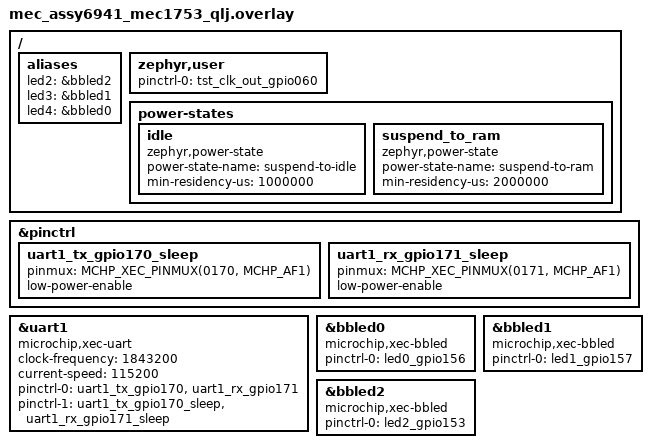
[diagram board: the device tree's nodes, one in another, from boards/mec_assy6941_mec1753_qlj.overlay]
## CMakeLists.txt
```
# Copyright (c) 2026 Microchip Technology Inc.
#
# SPDX-License-Identifier: Apache-2.0
#
cmake_minimum_required(VERSION 3.20.0)

find_package(Zephyr REQUIRED HINTS $ENV{ZEPHYR_BASE})
project(microchip_xec_pm_device)

file(GLOB app_sources src/*.c)

target_sources(app PRIVATE ${app_sources})
```

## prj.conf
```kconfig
# Enable config log
CONFIG_STDOUT_CONSOLE=y
CONFIG_LOG=y
CONFIG_LOG_BUFFER_SIZE=8096

CONFIG_LED=y

# use pseudo-random data for non-cryptographic test patterns
CONFIG_TEST_RANDOM_GENERATOR=y

# Use kernel triggered PM and driver PM_DEVICE
CONFIG_PM=y
CONFIG_PM_DEVICE=y

# make stepping code easier
#CONFIG_DEBUG=y
```

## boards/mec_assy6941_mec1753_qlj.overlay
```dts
/*
 * Copyright (c) 2026 Microchip Technology Inc.
 *
 * SPDX-License-Identifier: Apache-2.0
 */

/* mec_assy6941 EVB
 *
 * Set VTR2 to +3.3V
 * J68 2x8 1-2
 *
 */

#include <zephyr/dt-bindings/gpio/microchip-xec-gpio.h>

/* define sleep states for I2C pins */
&pinctrl {
	uart1_tx_gpio170_sleep: uart1_tx_gpio170_sleep {
		pinmux = <MCHP_XEC_PINMUX(0170, MCHP_AF1)>;
		low-power-enable;
	};

	uart1_rx_gpio171_sleep: uart1_rx_gpio171_sleep {
		pinmux = <MCHP_XEC_PINMUX(0171, MCHP_AF1)>;
		low-power-enable;
	};
};

/ {
	aliases {
		led2 = &bbled2;
		led3 = &bbled1;
		led4 = &bbled0;
	};

	/* Configure GPIO060 as test PLL clock out.
	 * We scope this pin to observe if PLL is turned off in deep sleep (suspend).
	 */
	zephyr,user {
		pinctrl-0 = <&tst_clk_out_gpio060>;
		pinctrl-names = "default";
	};

	power-states {
		idle: idle {
			compatible = "zephyr,power-state";
			power-state-name = "suspend-to-idle";
			min-residency-us = <1000000>;
		};

		suspend_to_ram: suspend_to_ram {
			compatible = "zephyr,power-state";
			power-state-name = "suspend-to-ram";
			min-residency-us = <2000000>;
		};
	};
};

&uart1 {
	compatible = "microchip,xec-uart";
	status = "okay";
	clock-frequency = <1843200>;
	current-speed = <115200>;
	pinctrl-0 = <&uart1_tx_gpio170 &uart1_rx_gpio171>;
	pinctrl-1 = <&uart1_tx_gpio170_sleep &uart1_rx_gpio171_sleep>;
	pinctrl-names = "default", "sleep";
};

&bbled0 {
	compatible = "microchip,xec-bbled";
	pinctrl-0 = <&led0_gpio156>;
	pinctrl-names = "default";
	status = "okay";
};

&bbled1 {
	compatible = "microchip,xec-bbled";
	pinctrl-0 = <&led1_gpio157>;
	pinctrl-names = "default";
	status = "okay";
};

&bbled2 {
	compatible = "microchip,xec-bbled";
	pinctrl-0 = <&led2_gpio153>;
	pinctrl-names = "default";
	status = "okay";
};
```

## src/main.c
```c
/*
 * Copyright (c) 2026 Microchip Technology Inc.
 *
 * SPDX-License-Identifier: Apache-2.0
 */

/*
 * PM device sample application
 * UART1 is used as the Zephyr console and shell
 */

#include <soc.h>
#include <string.h>
#include <zephyr/kernel.h>
#include <zephyr/device.h>
#include <zephyr/devicetree.h>
#include <zephyr/drivers/gpio.h>
#include <zephyr/drivers/led.h>
#include <zephyr/drivers/pinctrl.h>
#include <zephyr/dt-bindings/pinctrl/mchp-xec-pinctrl.h>
#include <zephyr/logging/log.h>
#include <zephyr/logging/log_ctrl.h>
#include <zephyr/pm/pm.h>
#include <zephyr/pm/device.h>
#include <zephyr/pm/policy.h>
#include <zephyr/pm/state.h>

LOG_MODULE_REGISTER(app, CONFIG_LOG_DEFAULT_LEVEL);

#define BOARD_LED2_NODE DT_ALIAS(led2)
#define BOARD_LED3_NODE DT_ALIAS(led3)
#define BOARD_LED4_NODE DT_ALIAS(led4)

#define ZEPHYR_CONSOLE_UART_NODE DT_CHOSEN(zephyr_console)

#define ZEPHYR_USER_NODE DT_PATH(zephyr_user)

/* Pin(s) needed to check PM suspend */
PINCTRL_DT_DEFINE(ZEPHYR_USER_NODE);

const bool uart1_is_wakeup_source = DT_PROP_OR(ZEPHYR_CONSOLE_UART_NODE, wakeup_source, 0);

const struct device *board_led2 = DEVICE_DT_GET(BOARD_LED2_NODE);
const struct device *board_led3 = DEVICE_DT_GET(BOARD_LED3_NODE);
const struct device *board_led4 = DEVICE_DT_GET(BOARD_LED4_NODE);

int main(void)
{
	int rc = 0;

#ifdef CONFIG_BOARD_QUALIFIERS
	LOG_INF("Microchip XEC PM device: board: %s/%s", CONFIG_BOARD, CONFIG_BOARD_QUALIFIERS);
#else
	LOG_INF("Microchip XEC I2Cv3 targ_mode: board: %s", CONFIG_BOARD);
#endif
#if DT_NODE_HAS_PROP(ZEPHYR_CONSOLE_UART_NODE, compatible)
	LOG_INF("UART console compatible: %s",
		DT_PROP_BY_IDX(ZEPHYR_CONSOLE_UART_NODE, compatible, 0));
#else
	LOG_INF("UART console node does not have a compatible!");
#endif

	const struct pinctrl_dev_config *zu_pcfg = PINCTRL_DT_DEV_CONFIG_GET(ZEPHYR_USER_NODE);

	rc = pinctrl_apply_state(zu_pcfg, PINCTRL_STATE_DEFAULT);
	if (rc != 0) {
		LOG_ERR("Failed to configure GPIO for TEST_CLK_OUT (%d)", rc);
	}

	/* disable LED HW app loaded from flash by Boot-ROM enabled
	 */
	led_off(board_led2, 0);
	led_off(board_led3, 0);
	led_off(board_led4, 0);

	while (true) {
		LOG_INF("sleep for 5000 milliseconds");

		led_off(board_led2, 0);

		k_sleep(K_MSEC(5000));

		led_on(board_led2, 0);

		LOG_INF("Wake from sleep");
		log_flush();
	}

	LOG_INF("Program End (rc=%d)", rc);
	log_flush();

	return 0;
}
```
